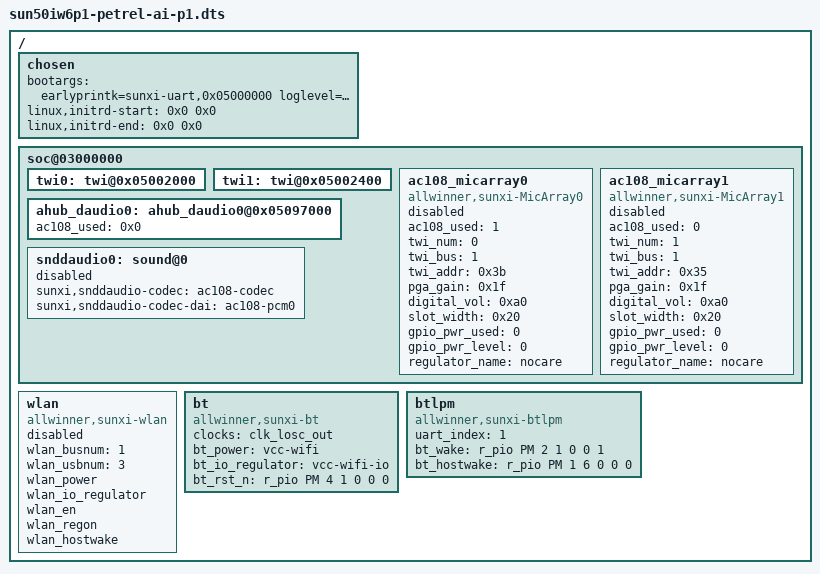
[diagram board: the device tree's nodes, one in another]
/*
 * Allwinner Technology CO., Ltd. sun50iw6p1 pro1 board.
 *
 * pro1 board support.
 */

/dts-v1/;

#include "sun50iw6p1.dtsi"

/{
	chosen {
		bootargs = "earlyprintk=sunxi-uart,0x05000000 loglevel=8 initcall_debug=1 console=ttyS0 init=/init";
		linux,initrd-start = <0x0 0x0>;
		linux,initrd-end = <0x0 0x0>;
	};

	soc@03000000 {
		twi0: twi@0x05002000{
			status = "okay";
		};
		twi1: twi@0x05002400{
			status = "okay";
                };

		ac108_micarray0: ac108_micarray0 {
			compatible = "allwinner,sunxi-MicArray0";
			ac108_used = <1>;
			twi_num = <0>;
			twi_bus = <1>;
			twi_addr = <0x3b>;
			pga_gain = <0x1f>;
			digital_vol = <0xa0>;
			slot_width = <0x20>;
			gpio_pwr_used = <0>;
			gpio_pwr_level = <0>;
			/*gpio-spk = <&r_pio PL 6 1 1 1 1>;*/
			regulator_name = "nocare";
			status = "disabled";
		};

		ac108_micarray1: ac108_micarray1 {
			compatible = "allwinner,sunxi-MicArray1";
			ac108_used = <0>;
			twi_num = <1>;
			twi_bus = <1>;
			twi_addr = <0x35>;
			pga_gain = <0x1f>;
			digital_vol = <0xa0>;
			slot_width = <0x20>;
			gpio_pwr_used = <0>;
			gpio_pwr_level = <0>;
			/*gpio-spk = <&r_pio PL 6 1 1 1 1>;*/
			regulator_name = "nocare";
			status = "disabled";
		};

		ahub_daudio0:ahub_daudio0@0x05097000{
			ac108_used = <0x0>;
		};

		snddaudio0:sound@0{
			/* ac108-codec throught mfd_add_devices */
			sunxi,snddaudio-codec = "ac108-codec";
			sunxi,snddaudio-codec-dai = "ac108-pcm0";
			status = "disabled";
		};

	};

	wlan:wlan {
		compatible = "allwinner,sunxi-wlan";
		wlan_busnum = <1>;
		wlan_usbnum = <3>;
		wlan_power;
		wlan_io_regulator;
		wlan_en;
		wlan_regon;
		wlan_hostwake;
		status = "disabled";
	};

	bt:bt {
		compatible = "allwinner,sunxi-bt";
		clocks = <&clk_losc_out>;
		bt_power = "vcc-wifi";
		bt_io_regulator = "vcc-wifi-io";
		bt_rst_n = <&r_pio PM 4 1 0 0 0>;
		status = "okay";
	};

	btlpm:btlpm {
		compatible = "allwinner,sunxi-btlpm";
		uart_index = <1>;
		bt_wake = <&r_pio PM 2 1 0 0 1>;
		bt_hostwake = <&r_pio PM 1 6 0 0 0>;
		status = "okay";
	};
};
